AUTOSAR XML (schema 00046)
package /ComponentTypes
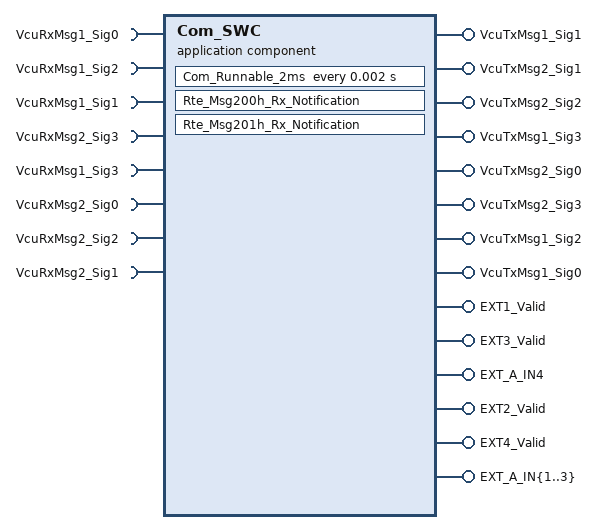
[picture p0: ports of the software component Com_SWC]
  application sw component type Com_SWC
    8 x require port:
      VcuRxMsg1_Sig0: nonqueued-receiver-com-spec{data-element=VcuRxMsg1_Sig0, alive-timeout=2, init-value=0}, required-interface=VcuRxMsg1_Sig0
      VcuRxMsg1_Sig2: nonqueued-receiver-com-spec{data-element=VcuRxMsg1_Sig2, alive-timeout=2, init-value=0}, required-interface=VcuRxMsg1_Sig2
      VcuRxMsg1_Sig1: nonqueued-receiver-com-spec{data-element=VcuRxMsg1_Sig1, alive-timeout=2, init-value=0}, required-interface=VcuRxMsg1_Sig1
      VcuRxMsg2_Sig3: nonqueued-receiver-com-spec{data-element=VcuRxMsg2_Sig3, alive-timeout=2, init-value=0}, required-interface=VcuRxMsg2_Sig3
      VcuRxMsg1_Sig3: nonqueued-receiver-com-spec{data-element=VcuRxMsg1_Sig3, alive-timeout=2, init-value=0}, required-interface=VcuRxMsg1_Sig3
      VcuRxMsg2_Sig0: nonqueued-receiver-com-spec{data-element=VcuRxMsg2_Sig0, alive-timeout=2, init-value=0}, required-interface=VcuRxMsg2_Sig0
      VcuRxMsg2_Sig2: nonqueued-receiver-com-spec{data-element=VcuRxMsg2_Sig2, alive-timeout=2, init-value=0}, required-interface=VcuRxMsg2_Sig2
      VcuRxMsg2_Sig1: nonqueued-receiver-com-spec{data-element=VcuRxMsg2_Sig1, alive-timeout=2, init-value=0}, required-interface=VcuRxMsg2_Sig1
    16 x provide port:
      VcuTxMsg1_Sig1: nonqueued-sender-com-spec{data-element=VcuTxMsg1_Sig1, init-value=0}, provided-interface=VcuTxMsg1_Sig1
      VcuTxMsg2_Sig1: nonqueued-sender-com-spec{data-element=VcuTxMsg2_Sig1, init-value=0}, provided-interface=VcuTxMsg2_Sig1
      VcuTxMsg2_Sig2: nonqueued-sender-com-spec{data-element=VcuTxMsg2_Sig2, init-value=0}, provided-interface=VcuTxMsg2_Sig2
      VcuTxMsg1_Sig3: nonqueued-sender-com-spec{data-element=VcuTxMsg1_Sig3, init-value=0}, provided-interface=VcuTxMsg1_Sig3
      VcuTxMsg2_Sig0: nonqueued-sender-com-spec{data-element=VcuTxMsg2_Sig0, init-value=0}, provided-interface=VcuTxMsg2_Sig0
      VcuTxMsg2_Sig3: nonqueued-sender-com-spec{data-element=VcuTxMsg2_Sig3, init-value=0}, provided-interface=VcuTxMsg2_Sig3
      VcuTxMsg1_Sig2: nonqueued-sender-com-spec{data-element=VcuTxMsg1_Sig2, init-value=0}, provided-interface=VcuTxMsg1_Sig2
      VcuTxMsg1_Sig0: nonqueued-sender-com-spec{data-element=VcuTxMsg1_Sig0, init-value=0}, provided-interface=VcuTxMsg1_Sig0
      EXT1_Valid: nonqueued-sender-com-spec{data-element=EXT1_Valid, init-value=0}, provided-interface=EXT1_Valid
      EXT3_Valid: nonqueued-sender-com-spec{data-element=EXT3_Valid, init-value=0}, provided-interface=EXT3_Valid
      EXT_A_IN4: nonqueued-sender-com-spec{data-element=EXT_A_IN4, init-value=0}, provided-interface=EXT_A_IN4
      EXT2_Valid: nonqueued-sender-com-spec{data-element=EXT2_Valid, init-value=0}, provided-interface=EXT2_Valid
      EXT4_Valid: nonqueued-sender-com-spec{data-element=EXT4_Valid, init-value=0}, provided-interface=EXT4_Valid
      EXT_A_IN{1..3}: nonqueued-sender-com-spec{data-element=EXT_A_IN{1..3}, init-value=0}, provided-interface=EXT_A_IN{1..3}
    behavior Com_SWC_InternalBehavior
      data received event DRT_Rte_Msg200h_Rx_Notification_VcuRxMsg1_Sig0_VcuRxMsg1_Sig0: start-on-event=Rte_Msg200h_Rx_Notification, data=VcuRxMsg1_Sig0.VcuRxMsg1_Sig0
      data received event DRT_Rte_Msg201h_Rx_Notification_VcuRxMsg2_Sig0_VcuRxMsg2_Sig0: start-on-event=Rte_Msg201h_Rx_Notification, data=VcuRxMsg2_Sig0.VcuRxMsg2_Sig0
      timing event TMT_Com_Runnable_2ms: start-on-event=Com_Runnable_2ms, period=0.002
      runnable Rte_Msg200h_Rx_Notification
      runnable Rte_Msg201h_Rx_Notification
      runnable Com_Runnable_2ms
        data-receive-point-by-arguments:
          8 x access:
            REC_VcuRxMsg1_Sig{0..3}_VcuRxMsg1_Sig{0..3}: accessed-variable=VcuRxMsg1_Sig{0..3}.VcuRxMsg1_Sig{0..3}
            REC_VcuRxMsg2_Sig{0..3}_VcuRxMsg2_Sig{0..3}: accessed-variable=VcuRxMsg2_Sig{0..3}.VcuRxMsg2_Sig{0..3}
        data-send-points:
          16 x access:
            SEND_VcuTxMsg1_Sig{0..3}_VcuTxMsg1_Sig{0..3}: accessed-variable=VcuTxMsg1_Sig{0..3}.VcuTxMsg1_Sig{0..3}
            SEND_VcuTxMsg2_Sig{0..3}_VcuTxMsg2_Sig{0..3}: accessed-variable=VcuTxMsg2_Sig{0..3}.VcuTxMsg2_Sig{0..3}
            SEND_EXT{1..4}_Valid_EXT{1..4}_Valid: accessed-variable=EXT{1..4}_Valid.EXT{1..4}_Valid
            SEND_EXT_A_IN{1..4}_EXT_A_IN{1..4}: accessed-variable=EXT_A_IN{1..4}.EXT_A_IN{1..4}
  swc implementation Com_SWC_Implementation: behavior=Com_SWC_InternalBehavior
